AUTOSAR XML (schema 00050)
standard types defined: uint8, uint16, sint16
package /DataTypes
  9 x app type, all with category=VALUE:
    StateOfCharge_T: base-type=uint8, compu-method=SocPercent_CM, unit=Percent
    CellVoltage_T: base-type=uint16, unit=Volt
    PackTemperature_T: base-type=sint16, unit=DegC
    TorqueDemand_T: base-type=sint16, unit=NewtonMetre
    MotorSpeed_T: base-type=sint16, unit=RevPerMin
    DCLinkVoltage_T: base-type=uint16, unit=Volt
    DriveMode_T
    ContactorState_T
    FaultSeverity_T
package /PortInterfaces
  9 x sender receiver interface:
    SocSR_I
      data StateOfCharge: type=StateOfCharge_T
    CellVoltageSR_I
      data MinCellVoltage: type=CellVoltage_T
      data MaxCellVoltage: type=CellVoltage_T
    PackTempSR_I
      data PackTemperature: type=PackTemperature_T
      data MaxCellTemperature: type=PackTemperature_T
    TorqueDemandSR_I
      data TorqueDemand: type=TorqueDemand_T
      data RegenTorqueLimit: type=TorqueDemand_T
    MotorSpeedSR_I
      data MotorSpeedActual: type=MotorSpeed_T
    DCLinkSR_I
      data DCLinkVoltage: type=DCLinkVoltage_T
    DriveModeSR_I
      data DriveMode: type=DriveMode_T
    ContactorSR_I
      data MainContactorCmd: type=ContactorState_T
      data PrechargeContactorCmd: type=ContactorState_T
    FaultSR_I
      data FaultSeverity: type=FaultSeverity_T
      data FaultCode: type=uint16
  client server interface ContactorControl_CS_I
    operation CloseMainContactor
      arg result: type=uint8, direction=OUT
    operation OpenMainContactor
      arg result: type=uint8, direction=OUT
  client server interface DiagEventReport_CS_I
    operation ReportFaultDetected
      arg faultCode: type=uint16, direction=IN
      arg severity: type=FaultSeverity_T, direction=IN
package /SWComponents
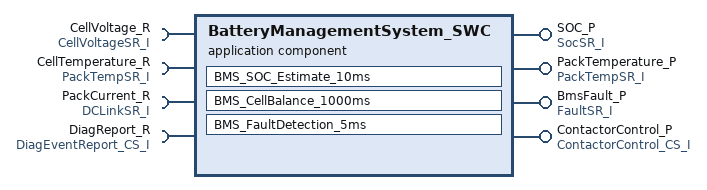
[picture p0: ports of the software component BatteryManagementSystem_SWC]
  application sw component type BatteryManagementSystem_SWC
    require port CellVoltage_R: required-interface=CellVoltageSR_I
    require port CellTemperature_R: required-interface=PackTempSR_I
    require port PackCurrent_R: required-interface=DCLinkSR_I
    4 x provide port:
      SOC_P: provided-interface=SocSR_I
      PackTemperature_P: provided-interface=PackTempSR_I
      BmsFault_P: provided-interface=FaultSR_I
      ContactorControl_P: provided-interface=ContactorControl_CS_I
    require port DiagReport_R: required-interface=DiagEventReport_CS_I
    behavior BMS_IB
      runnable BMS_SOC_Estimate_10ms: minimum-start-interval=0.01
        data-read-access:
          access ReadCellVoltage: accessed-variable=CellVoltage_R.MinCellVoltage
        data-write-access:
          access WriteSOC: accessed-variable=SOC_P.StateOfCharge
      runnable BMS_CellBalance_1000ms: minimum-start-interval=1.0
      runnable BMS_FaultDetection_5ms: minimum-start-interval=0.005
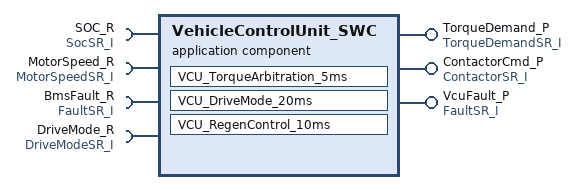
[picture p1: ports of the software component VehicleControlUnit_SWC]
  application sw component type VehicleControlUnit_SWC
    4 x require port:
      SOC_R: required-interface=SocSR_I
      MotorSpeed_R: required-interface=MotorSpeedSR_I
      BmsFault_R: required-interface=FaultSR_I
      DriveMode_R: required-interface=DriveModeSR_I
    provide port TorqueDemand_P: provided-interface=TorqueDemandSR_I
    provide port ContactorCmd_P: provided-interface=ContactorSR_I
    provide port VcuFault_P: provided-interface=FaultSR_I
    behavior VCU_IB
      runnable VCU_TorqueArbitration_5ms: minimum-start-interval=0.005
      runnable VCU_DriveMode_20ms: minimum-start-interval=0.02
      runnable VCU_RegenControl_10ms: minimum-start-interval=0.01
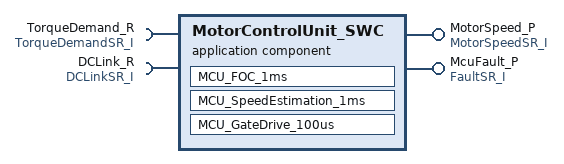
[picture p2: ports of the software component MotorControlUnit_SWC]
  application sw component type MotorControlUnit_SWC
    require port TorqueDemand_R: required-interface=TorqueDemandSR_I
    require port DCLink_R: required-interface=DCLinkSR_I
    provide port MotorSpeed_P: provided-interface=MotorSpeedSR_I
    provide port McuFault_P: provided-interface=FaultSR_I
    behavior MCU_IB
      runnable MCU_FOC_1ms: minimum-start-interval=0.001
      runnable MCU_SpeedEstimation_1ms: minimum-start-interval=0.001
      runnable MCU_GateDrive_100us: minimum-start-interval=0.0001
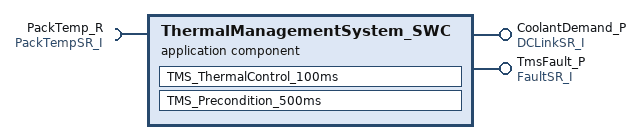
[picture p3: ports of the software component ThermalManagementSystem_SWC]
  application sw component type ThermalManagementSystem_SWC
    require port PackTemp_R: required-interface=PackTempSR_I
    provide port CoolantDemand_P: provided-interface=DCLinkSR_I
    provide port TmsFault_P: provided-interface=FaultSR_I
    behavior TMS_IB
      runnable TMS_ThermalControl_100ms: minimum-start-interval=0.1
      runnable TMS_Precondition_500ms: minimum-start-interval=0.5
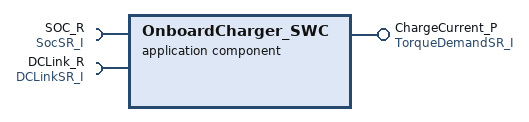
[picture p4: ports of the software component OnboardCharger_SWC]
  application sw component type OnboardCharger_SWC
    require port SOC_R: required-interface=SocSR_I
    require port DCLink_R: required-interface=DCLinkSR_I
    provide port ChargeCurrent_P: provided-interface=TorqueDemandSR_I
package /Compositions
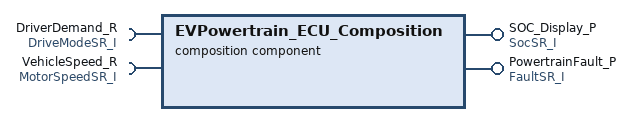
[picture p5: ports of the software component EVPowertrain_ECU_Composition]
  composition sw component type EVPowertrain_ECU_Composition
    require port DriverDemand_R: required-interface=DriveModeSR_I
    require port VehicleSpeed_R: required-interface=MotorSpeedSR_I
    provide port SOC_Display_P: provided-interface=SocSR_I
    provide port PowertrainFault_P: provided-interface=FaultSR_I
    5 x component:
      BMS: type=BatteryManagementSystem_SWC
      VCU: type=VehicleControlUnit_SWC
      MCU: type=MotorControlUnit_SWC
      TMS: type=ThermalManagementSystem_SWC
      OBC: type=OnboardCharger_SWC
    connect BMS.SOC_P -> VCU.SOC_R
    connect BMS.SOC_P -> OBC.SOC_R
    connect BMS.PackTemperature_P -> TMS.PackTemp_R
    connect VCU.TorqueDemand_P -> MCU.TorqueDemand_R
    connect MCU.MotorSpeed_P -> VCU.MotorSpeed_R
    connect BMS.BmsFault_P -> VCU.BmsFault_R
package /EcuConfiguration
  ecu instance EVPowertrain_ECU
    com controller CAN_Controller_HS
    com controller CAN_Controller_PT
